# R7FA2L1AB register map
Vendor: Renesas Electronics Corporation; Series: RA2L1; File version: 0.50.00
CPU: CM23 r1p0, little endian, MPU, no FPU, VTOR, 2 interrupt priority bits, 32 interrupts
Registers are 8-bit, read-write, reset 0x0 unless marked. A register's access mark holds for its fields unless they carry their own. Offsets are from the block's base; [hi:lo] are bit positions; lines under a group give offsets from that group; {n}, {i} and the like mark numbered series; 'fields as' and 'values as' point back to an identical list; <NAME> marks a mode.

## ADC12 — 12-bit A/D Converter
Base 0x4005C000
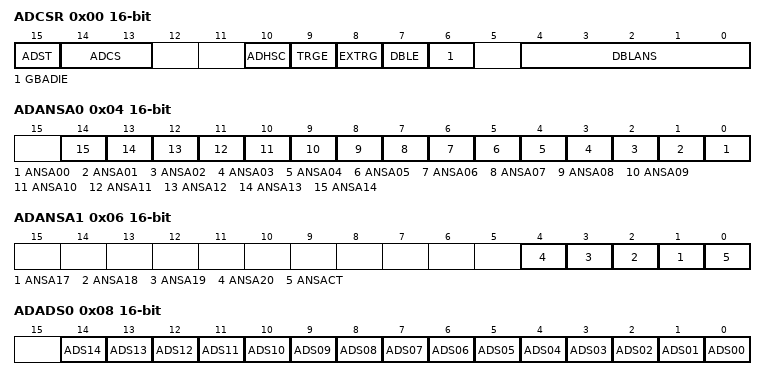
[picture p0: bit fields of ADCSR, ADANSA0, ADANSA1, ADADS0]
0x00 ADCSR 16-bit — A/D Control Register
  [15] ADST — A/D Conversion Start
    0=Stop A/D conversion process; 1=Start A/D conversion process
  [14:13] ADCS — Scan Mode Select
    0=Single scan mode; 1=Group scan mode; 2=Continuous scan mode; 3=Setting prohibited
  [10] ADHSC — A/D Conversion Mode Select
    0=High-speed A/D conversion mode; 1=Low-power A/D conversion mode
  [9] TRGE — Trigger Start Enable
    0=Disable A/D conversion to be started by the synchronous or asynchronous trigger; 1=Enable A/D conversion to be started by the synchronous or asynchronous trigger
  [8] EXTRG — Trigger Select
    0=Start A/D conversion by the synchronous trigger (ELC); 1=Start A/D conversion by the asynchronous trigger (ADTRG0)
  [7] DBLE — Double Trigger Mode Select
    0=Deselect double-trigger mode; 1=Select double-trigger mode
  [6] GBADIE — Group B Scan End Interrupt and ELC Event Enable
    0=Disable ADC120_GBADI interrupt generation on group B scan completion; 1=Enable ADC120_GBADI interrupt generation on group B scan completion
  [4:0] DBLANS — Double Trigger Channel Select
0x04 ADANSA0 16-bit — A/D Channel Select Register A0
  [all] fields
    0=Do not select associated input channel; 1=Select associated input channel
  [n] ANSA{n:02} (n=0..14) — A/D Conversion Channels Select
0x06 ADANSA1 16-bit — A/D Channel Select Register A1
  [n-16] ANSA{n} (n=17..20) — A/D Conversion Channels Select
    values as the fields of ADANSA0
  [0] ANSACT — A/D Conversion Channels CTSU TSCAP Voltage Select
    0=Do not select CTSU TSCAP voltage; 1=Select CTSU TSCAP voltage
0x08 ADADS0 16-bit — A/D-Converted Value Addition/Average Channel Select Register 0
  [all] fields
    values as the fields of ADANSA0
  [n] ADS{n:02} (n=0..14) — A/D-Converted Value Addition/Average Channel Select
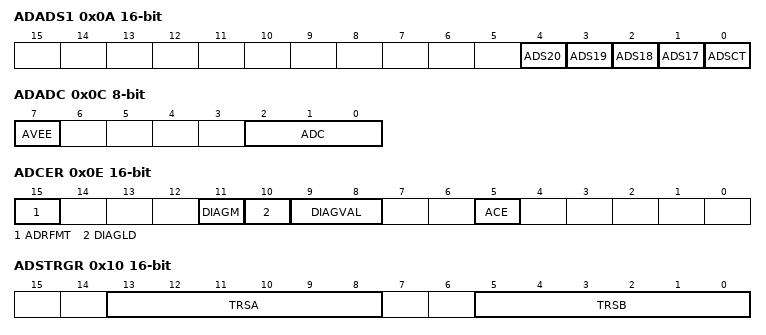
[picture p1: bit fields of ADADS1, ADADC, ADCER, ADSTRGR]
0x0A ADADS1 16-bit — A/D-Converted Value Addition/Average Channel Select Register 1
  [n-16] ADS{n} (n=17..20) — A/D-Converted Value Addition/Average Channel Select
    values as the fields of ADANSA0
  [0] ADSCT — A/D-Converted Value Addition/Average CTSU TSCAP Voltage Select
    0=CTSU TSCAP voltage not selected; 1=CTSU TSCAP voltage selected
0x0C ADADC — A/D-Converted Value Addition/Average Count Select Register
  [7] AVEE — Average Mode Enable
    0=Disable average mode; 1=Enable average mode
  [2:0] ADC — Count Select
    0=1-time conversion (no addition, same as normal conversion); 1=2-time conversion (one addition); 2=3-time conversion (two additions); 3=4-time conversion (three additions); 5=16-time conversion (15 additions); other=Others (Setting prohibited)
0x0E ADCER 16-bit — A/D Control Extended Register
  [15] ADRFMT — A/D Data Register Format Select
    0=Select right-justified for the A/D data register format; 1=Select left-justified for the A/D data register format
  [11] DIAGM — Self-Diagnosis Enable
    0=Disable ADC12 self-diagnosis; 1=Enable ADC12 self-diagnosis
  [10] DIAGLD — Self-Diagnosis Mode Select
    0=Select rotation mode for self-diagnosis voltage; 1=Select mixed mode for self-diagnosis voltage
  [9:8] DIAGVAL — Self-Diagnosis Conversion Voltage Select
    0=Setting prohibited when self-diagnosis is enabled; 1=0 volts; 2=Reference power supply voltage × 1/2; 3=Reference power supply voltage
  [5] ACE — A/D Data Register Automatic Clearing Enable
    0=Disable automatic clearing; 1=Enable automatic clearing
0x10 ADSTRGR 16-bit — A/D Conversion Start Trigger Select Register
  [13:8] TRSA — A/D Conversion Start Trigger Select
  [5:0] TRSB — A/D Conversion Start Trigger Select for Group B
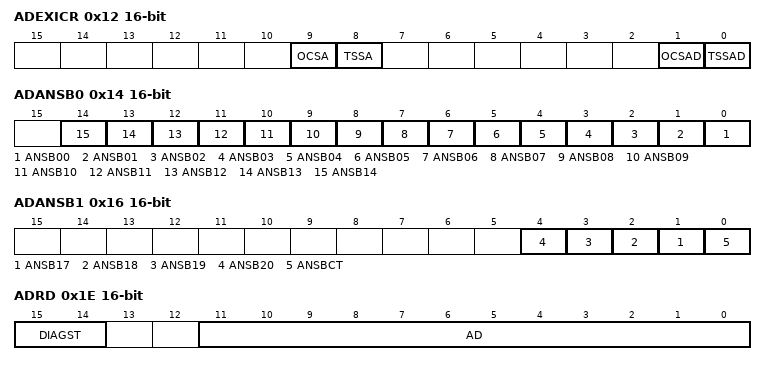
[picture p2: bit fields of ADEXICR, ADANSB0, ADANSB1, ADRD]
0x12 ADEXICR 16-bit — A/D Conversion Extended Input Control Registers
  [9] OCSA — Internal Reference Voltage A/D Conversion Select
    0=Disable A/D conversion of internal reference voltage; 1=Enable A/D conversion of internal reference voltage
  [8] TSSA — Temperature Sensor Output A/D Conversion Select
    0=Disable A/D conversion of temperature sensor output; 1=Enable A/D conversion of temperature sensor output
  [1] OCSAD — Internal Reference Voltage A/D-Converted Value Addition/Average Mode Select
    0=Do not select addition/average mode for internal reference voltage; 1=Select addition/average mode for internal reference voltage
  [0] TSSAD — Temperature Sensor Output A/D-Converted Value Addition/Average Mode Select
    0=Do not select addition/average mode for temperature sensor output; 1=Select addition/average mode for temperature sensor output
0x14 ADANSB0 16-bit — A/D Channel Select Register B0
  [all] fields
    values as the fields of ADANSA0
  [n] ANSB{n:02} (n=0..14) — A/D Conversion Channels Select
0x16 ADANSB1 16-bit — A/D Channel Select Register B1
  [n-16] ANSB{n} (n=17..20) — A/D Conversion Channels Select
    values as the fields of ADANSA0
  [0] ANSBCT — A/D Conversion Channels CTSU TSCAP Voltage Select
    values as ADADS1.ADSCT
0x18 ADDBLDR 16-bit ro — A/D Data Duplexing Register
  [15:0] ADDBLDR — Value 15 to 0
0x1A ADTSDR 16-bit ro — A/D Temperature Sensor Data Register
  [15:0] ADTSDR — Value 15 to 0
0x1C ADOCDR 16-bit ro — A/D Internal Reference Voltage Data Register
  [15:0] ADOCDR — Value 15 to 0
0x1E ADRD 16-bit ro — A/D Self-Diagnosis Data Register
  [15:14] DIAGST — Self-Diagnosis Status
    0=Self-diagnosis not executed after power-on; 1=Self-diagnosis was executed using the 0 V voltage; 2=Self-diagnosis was executed using the reference power supply voltage x 1/2; 3=Self-diagnosis was executed using the reference power supply voltage
  [11:0] AD — Converted Value 11 to 0
{0x20+2i} ADDR{i} (i=0..14) 16-bit ro — A/D Data Registers {i}
  [15:0] ADDRn — Value 15 to 0
0x40 ADCTDR 16-bit ro — A/D CTSU TSCAP Voltage Data Register
  [15:0] ADCTDR — Value 15 to 0
{0x20+2i} ADDR{i} (i=17..20) 16-bit ro — A/D Data Registers {i}
  [15:0] ADDRn — Value 15 to 0
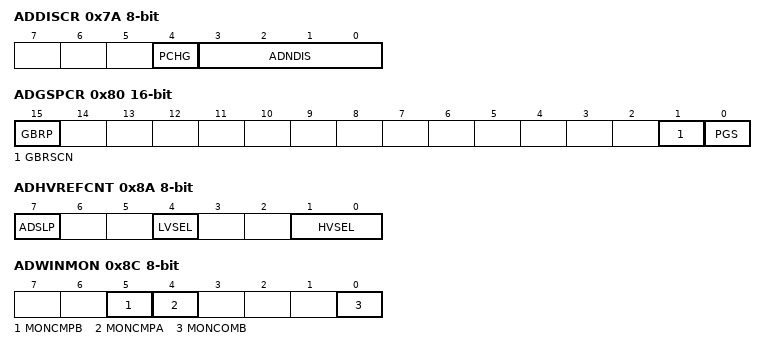
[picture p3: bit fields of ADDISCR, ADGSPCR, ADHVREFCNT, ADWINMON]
0x7A ADDISCR — A/D Disconnection Detection Control Register
  [4] PCHG — Precharge/discharge select
    0=Discharge; 1=Precharge
  [3:0] ADNDIS — Disconnection Detection Assist Setting
    0=The disconnection detection assist function is disabled; 1=Setting prohibited; other=Others (The number of states for the discharge or precharge period.)
0x7E ADACSR — A/D Conversion Operation Mode Select Register
  [1] ADSAC — Successive Approximation Control Setting
    0=Normal conversion mode (default); 1=Fast conversion mode
0x80 ADGSPCR 16-bit — A/D Group Scan Priority Control Register
  [15] GBRP — Group B Single Scan Continuous Start
    0=Do not continuously activate single scan for group B; 1=Continuously activate single scan for group B
  [1] GBRSCN — Group B Restart Setting
    0=Do not restart group B scanning after it is stopped by group A priority control; 1=Restart group B scanning after it is stopped by group A priority control
  [0] PGS — Group A Priority Control Setting
    0=Operate without group A priority control; 1=Operate with group A priority control
0x84 ADDBLDRA 16-bit ro — A/D Data Duplexing Register A
  [15:0] ADDBLDRn — Value 15 to 0
0x86 ADDBLDRB 16-bit ro — A/D Data Duplexing Register B
  [15:0] ADDBLDRn — Value 15 to 0
0x8A ADHVREFCNT — A/D High-Potential/Low-Potential Reference Voltage Control Register
  [7] ADSLP — Sleep
    0=Normal operation; 1=Standby state
  [4] LVSEL — Low-Potential Reference Voltage Select
    0=AVSS0 is selected as the low-potential reference voltage; 1=VREFL0 is selected as the low-potential reference voltage
  [1:0] HVSEL — High-Potential Reference Voltage Select
    0=AVCC0 is selected as the high-potential reference voltage; 1=VREFH0 is selected as the high-potential reference voltage; 2=Internal reference voltage is selected as the high-potential reference voltage; 3=Internal node discharge (no reference voltage pin is selected)
0x8C ADWINMON ro — A/D Compare Function Window A/B Status Monitor Register
  [5] MONCMPB — Comparison Result Monitor B
    0=Window B comparison conditions are not met; 1=Window B comparison conditions are met
  [4] MONCMPA — Comparison Result Monitor A
    0=Window A comparison conditions are not met; 1=Window A comparison conditions are met
  [0] MONCOMB — Combination Result Monitor
    0=Window A/B composite conditions are not met; 1=Window A/B composite conditions are met
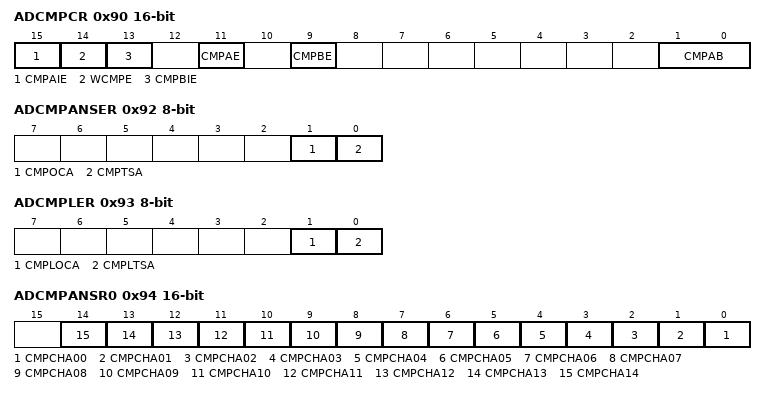
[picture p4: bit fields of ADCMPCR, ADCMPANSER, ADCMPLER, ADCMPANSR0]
0x90 ADCMPCR 16-bit — A/D Compare Function Control Register
  [15] CMPAIE — Compare A Interrupt Enable
    0=Disable ADC120_CMPAI interrupt when comparison conditions (window A) are met; 1=Enable ADC120_CMPAI interrupt when comparison conditions (window A) are met
  [14] WCMPE — Window Function Setting
    0=Disable window function Window A and window B operate as a comparator to compare the single value on the lower side with the A/D conversion result; 1=Enable window function Window A and window B operate as a comparator to compare the two values on the upper and lower sides with the A/D conversion result
  [13] CMPBIE — Compare B Interrupt Enable
    0=Disable ADC120_CMPBI interrupt when comparison conditions (window B) are met; 1=Enable ADC120_CMPBI interrupt when comparison conditions (window B) are met
  [11] CMPAE — Compare Window A Operation Enable
    0=Disable compare window A operation. Disable ADC120_WCMPM and ADC120_WCMPUM outputs.; 1=Enable compare window A operation
  [9] CMPBE — Compare Window B Operation Enable
    0=Disable compare window B operation. Disable ADC120_WCMPM and ADC120_WCMPUM outputs.; 1=Enable compare window B operation
  [1:0] CMPAB — Window A/B Composite Conditions Setting
    0=Output ADC120_WCMPM when window A OR window B comparison conditions are met. Otherwise, output ADC120_WCMPUM.; 1=Output ADC120_WCMPM when window A EXOR window B comparison conditions are met. Otherwise, output ADC120_WCMPUM.; 2=Output ADC120_WCMPM when window A AND window B comparison conditions are met. Otherwise, output ADC120_WCMPUM.; 3=Setting prohibited
0x92 ADCMPANSER — A/D Compare Function Window A Extended Input Select Register
  [1] CMPOCA — Internal Reference Voltage Compare Select
    0=Exclude the internal reference voltage from the compare Window A target range; 1=Include the internal reference voltage in the compare Window A target range
  [0] CMPTSA — Temperature Sensor Output Compare Select
    0=Exclude the temperature sensor output from the compare Window A target range; 1=Include the temperature sensor output in the compare Window A target range
0x93 ADCMPLER — A/D Compare Function Window A Extended Input Comparison Condition Setting Register
  [1] CMPLOCA — Compare Window A Internal Reference Voltage Comparison Condition Select
    0=When window function is disabled (ADCMPCR.WCMPE = 0) : ADCMPDR0 value > A/D-converted value When window function is enabled (ADCMPCR.WCMPE = 1): A/D-converted value < ADCMPDR0 value, or A/D-converted value > ADCMPDR1 value; 1=When window function is disabled (ADCMPCR.WCMPE = 0): ADCMPDR0 value < A/D-converted value When window function is enabled (ADCMPCR.WCMPE = 1): ADCMPDR0 value < A/D-converted value < ADCMPDR1 value
  [0] CMPLTSA — Compare Window A Temperature Sensor Output Comparison Condition Select
    0=When window function is disabled (ADCMPCR.WCMPE = 0) : ADCMPDR0 value > A/D-converted value When window function is enabled (ADCMPCR.WCMPE = 1) : A/D-converted value < ADCMPDR0 value, or A/D-converted value > ADCMPDR1 value; 1=When window function is disabled (ADCMPCR.WCMPE = 0) : ADCMPDR0 value < A/D-converted value When window function is enabled (ADCMPCR.WCMPE = 1) : ADCMPDR0 value < A/D-converted value < ADCMPDR1 value
0x94 ADCMPANSR0 16-bit — A/D Compare Function Window A Channel Select Register 0
  [all] fields
    0=Disable compare function for associated input channel; 1=Enable compare function for associated input channel
  [n] CMPCHA{n:02} (n=0..14) — Compare Window A Channel Select
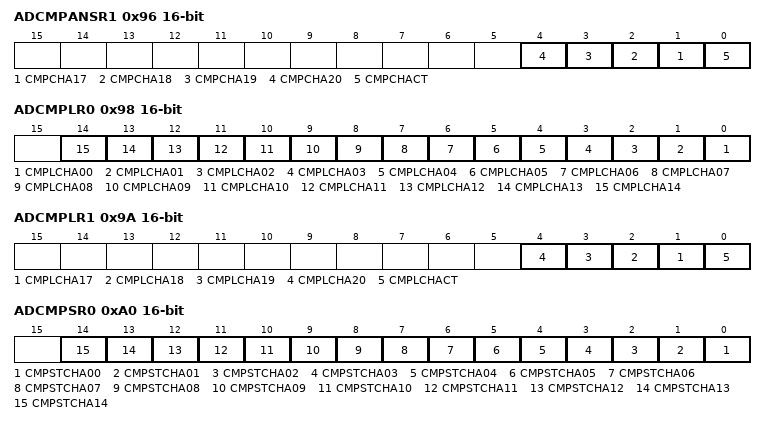
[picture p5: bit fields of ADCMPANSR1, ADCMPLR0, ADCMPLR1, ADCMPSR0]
0x96 ADCMPANSR1 16-bit — A/D Compare Function Window A Channel Select Register 1
  [n-16] CMPCHA{n} (n=17..20) — Compare Window A Channel Select
    values as the fields of ADCMPANSR0
  [0] CMPCHACT — Compare Window A CTSU TSCAP Voltage Select
    0=Compare function disabled for CTSU TSCAP voltage; 1=Compare function enabled for CTSU TSCAP voltage
0x98 ADCMPLR0 16-bit — A/D Compare Function Window A Comparison Condition Setting Register 0
  [all] fields
    0=When window function is disabled (ADCMPCR.WCMPE = 0): ADCMPDR0 value > A/D-converted value When window function is enabled (ADCMPCR.WCMPE = 1): A/D-converted value < ADCMPDR0 value, or ADCMPDR1 value < A/D-converted value; 1=When window function is disabled (ADCMPCR.WCMPE = 0): ADCMPDR0 value < A/D-converted value When window function is enabled (ADCMPCR.WCMPE = 1): ADCMPDR0 value < A/D-converted value < ADCMPDR1 value
  [n] CMPLCHA{n:02} (n=0..14) — Compare Window A Comparison Condition Select
0x9A ADCMPLR1 16-bit — A/D Compare Function Window A Comparison Condition Setting Register 1
  [n-16] CMPLCHA{n} (n=17..20) — Compare Window A Comparison Condition Select
    values as the fields of ADCMPLR0
  [0] CMPLCHACT — Compare Window A Comparison Condition Select for CTSU TSCAP Voltage
    0=When window function is disabled (ADCMPCR.WCMPE = 0): ADCMPDR0 value > A/D-converted value When window function is enabled (ADCMPCR.WCMPE = 1): A/D-converted value < ADCMPDR0 value or ADCMPDR1 value < A/D-converted value; 1=When window function is disabled (ADCMPCR.WCMPE = 0): ADCMPDR0 value < A/D-converted value When window function is enabled (ADCMPCR.WCMPE = 1): ADCMPDR0 value < A/D-converted value < ADCMPDR1 value
{0x9C+2i} ADCMPDR{i} (i=0..1) 16-bit — A/D Compare Function Window A Lower-Side/Upper-Side Level Setting Register
0xA0 ADCMPSR0 16-bit — A/D Compare Function Window A Channel Status Register 0
  [all] fields
    0=Comparison conditions are not met; 1=Comparison conditions are met
  [n] CMPSTCHA{n:02} (n=0..14) — Compare Window A Flag
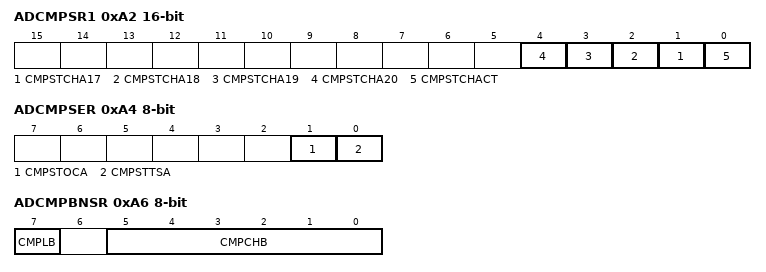
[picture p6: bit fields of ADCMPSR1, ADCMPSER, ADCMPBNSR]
0xA2 ADCMPSR1 16-bit — A/D Compare Function Window A Channel Status Register1
  [n-16] CMPSTCHA{n} (n=17..20) — Compare Window A Flag
    values as the fields of ADCMPSR0
  [0] CMPSTCHACT — Compare Window A Flag
    0=Comparison conditions not met; 1=Comparison conditions met
0xA4 ADCMPSER — A/D Compare Function Window A Extended Input Channel Status Register
  [1] CMPSTOCA — Compare Window A Internal Reference Voltage Compare Flag
    values as the fields of ADCMPSR0
  [0] CMPSTTSA — Compare Window A Temperature Sensor Output Compare Flag
    values as the fields of ADCMPSR0
0xA6 ADCMPBNSR — A/D Compare Function Window B Channel Select Register
  [7] CMPLB — Compare Window B Comparison Condition Setting
    0=When window function is disabled (ADCMPCR.WCMPE = 0): ADWINLLB value > A/D-converted value When window function is enabled (ADCMPCR.WCMPE = 1): A/D-converted value < ADWINLLB value, or ADWINULB value < A/D-converted value; 1=When window function is disabled (ADCMPCR.WCMPE = 0): ADWINLLB value < A/D-converted value When window function is enabled (ADCMPCR.WCMPE = 1): ADWINLLB value < A/D-converted value < ADWINULB value
  [5:0] CMPCHB — Compare Window B Channel Select
0xA8 ADWINLLB 16-bit — A/D Compare Function Window B Lower-Side/Upper-Side Level Setting Register
0xAA ADWINULB 16-bit — A/D Compare Function Window B Lower-Side/Upper-Side Level Setting Register
0xAC ADCMPBSR — A/D Compare Function Window B Status Register
  [0] CMPSTB — Compare Window B Flag
    values as the fields of ADCMPSR0
0xDD ADSSTRL reset 0xD — A/D Sampling State Register
  [7:0] SST — Sampling Time Setting
0xDE ADSSTRT reset 0xD — A/D Sampling State Register
  [7:0] SST — Sampling Time Setting
0xDF ADSSTRO reset 0xD — A/D Sampling State Register
  [7:0] SST — Sampling Time Setting
{0xE0+i} ADSSTR{i} (i=0..14) reset 0xD — A/D Sampling State Register
  [7:0] SST — Sampling Time Setting
